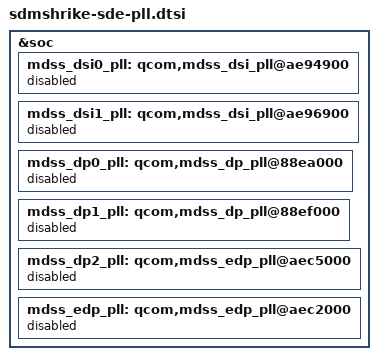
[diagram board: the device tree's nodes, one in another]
&soc {
	mdss_dsi0_pll: qcom,mdss_dsi_pll@ae94900 {
			status = "disabled";
		};

	mdss_dsi1_pll: qcom,mdss_dsi_pll@ae96900 {
			status = "disabled";
		};

	mdss_dp0_pll: qcom,mdss_dp_pll@88ea000 {
			status = "disabled";
		};

	mdss_dp1_pll: qcom,mdss_dp_pll@88ef000 {
			status = "disabled";
		};

	mdss_dp2_pll: qcom,mdss_edp_pll@aec5000 {
			status = "disabled";
		};

	mdss_edp_pll: qcom,mdss_edp_pll@aec2000 {
			status = "disabled";
		};

};
